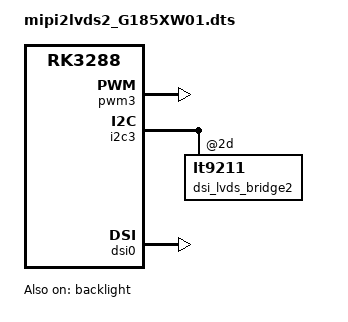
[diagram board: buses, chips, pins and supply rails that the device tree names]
/dts-v1/;
/plugin/;
/ {
	compatible = "rockchip,rk3288-evb-rk808-linux", "rockchip,rk3288";

	fragment@0 {
		target = <&pwm3>;
		__overlay__ {
			status = "okay";
		};
	};
	fragment@1 {
		target = <&backlight>;
		__overlay__ {
			status = "okay";
			pwms = <&pwm3 0 4000000 0>;
            enable_delay = <10>;
            minimal-brightness-level = <26>;
		};
	};
	fragment@2 {
		target = <&i2c3>;
		__overlay__ {
			status = "okay";
			dsi_lvds_bridge2: lt9211@2d {
				status = "okay";
				lvds-format = <2>;//VESA
				lvds-bpp = <24>;
				lvds-width-mm = <409>;
				lvds-height-mm = <230>;
				de-mode;
				//test-pattern;

				t1=<1>;//VCC on to start lvds signal
				t2=<500>;//LVDS signal(start) to turn Backlihgt on
				t3=<200>;//Backlihgt(off) to stop lvds signal
				t4=<1>;//LVDS signal to turn VCC off
				t5=<1000>;//VCC off to turn VCC on

				width-mm = <409>;
				height-mm = <230>;
				bpc=<8>;
				bus-format = <0x100a>;//<MEDIA_BUS_FMT_RGB888_1X24>;
				dsi,flags = <0x3>;
				dsi,format = <0>;
				dsi,lanes = <2>;

				display-timings {
					lvds {
						clock-frequency = <75000000>;
						hactive = <1366>;
						vactive = <768>;
						hfront-porch = <70>;
						hback-porch = <80>;
						hsync-len = <34>;
						vfront-porch = <15>;
						vsync-len = <8>;
						vback-porch = <15>;
						hsync-active = <0>;
						vsync-active = <0>;
						de-active = <1>;
						pixelclk-active = <0>;
					};
				};
			};
		};
	};
	fragment@3 {
		target = <&dsi0>;
		__overlay__ {
			status = "okay";
			rockchip,lane-rate=<920>;
			mipi_panel: mipi-panel {
				status = "disabled";
			};
		};
	};
	fragment@4 {
		target = <&pinctrl>;
		__overlay__ {
			gpio_init_config {
				gpio_init: gpio-init {
                                           rockchip,pins =
						<7 22 3 &pcfg_pull_none>;
				};
			};
		};
	};

};
